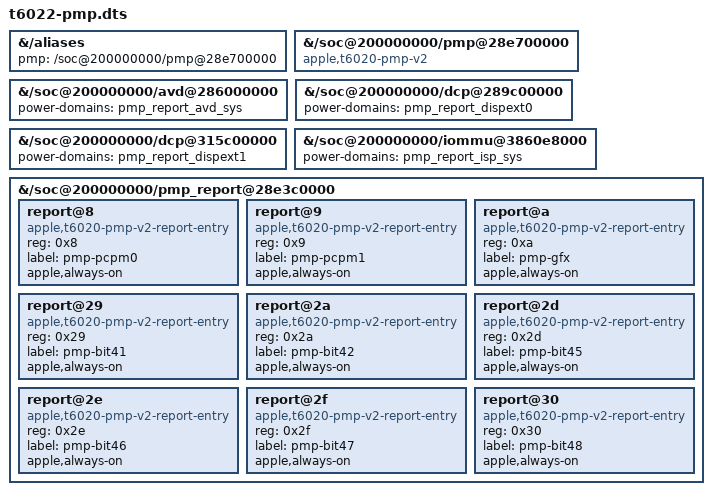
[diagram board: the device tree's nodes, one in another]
// SPDX-License-Identifier: GPL-2.0+ OR MIT
/*
 * The power management processor (PMP) on the M2 Ultra Mac Studio: Asahi's APPLE_USE_PMP for t6022-j475d as an
 * overlay, for die 0, with what that define gets wrong on this machine left out.
 *
 * Asahi's PMP support (drivers/soc/apple/pmp.rs, on for M1 Pro/Max/Ultra since 7.0) is off unless the device tree
 * is built with APPLE_USE_PMP. The define adds the "pmp" alias, which makes m1n1 (1.6.0 and later) copy the ADT's
 * iop-pmp-nub properties into the pmp node as apple,tunable-* and set it okay, and it moves the devices that vote
 * through the PMP report onto its entries. This overlay does the same for die 0; checked 3 Nov 2026 against
 * src/linux (asahi-7.1.13-3 plus the lab series) built with the define: the trees differ only in die 1.
 *
 * Die 1 is not here because Asahi's t6022 wiring for it is wrong (AsahiLinux/linux asahi 414e55d alike):
 *  - its AVD points at pmp_report_avd_sys_die1, which no file defines, so the tree does not compile;
 *  - its two DCPs move to report@1f and report@20, which are die 0's DISPEXT2 and DISPEXT3 (ADT soc-device IDs
 *    32 and 33), and those nodes stay disabled, so the HDMI port's DCP would never get its power domain.
 * The ADT (macOS re-ioreg-IODeviceTree, 28 Oct) gives die 1's devices die 0's soc-device IDs plus 64 (AVD1 82,
 * DISPEXT4 79 for the HDMI port), so die 1 votes in the report's second request word, which pmp-report does not
 * drive. kernel/pmp.sh can set them with its lab module (pmp_votes, VOTES_DIE1=1), but does not by default: macOS
 * wrote no word 1 in the boot traced on 4 Nov, and that day the HDMI display stayed fine with the PMP running and
 * word 1 empty.
 *
 * The pmp node's compatible is cut to "apple,t6020-pmp-v2": the stock pmp.ko matches "apple,t6000-pmp-v2" only and
 * would start the PMP with the M1 family's boot arguments. The lab's pmp series (src-patches/linux/pmp) matches
 * t6020 with the M2 family's, so a kernel built with it starts the PMP at boot; without the series nothing binds
 * and kernel/pmp.sh can start it by hand (votes, start --now).
 *
 * The request word as macOS has it when it starts the PMP (0x0001e6006000c700, traced 4 Nov): the stock entries
 * set DISPEXT0/1 (bits 14, 15) and AFNC4/5_IOA (29, 30) at boot; the entries added below, always on as those are,
 * set the P-CPU clusters (8, 9), the GPU (10) and bits 41, 42 and 45-48, which macOS sets one each after its device
 * requests and no soc-device or pmgr entry names. pmp-report sets an always-on entry's bit when it probes, which is
 * before the pmp module loads. Bits past 31 need the series' first patch (a 64-bit bit in pmp-report).
 *
 * m1n1 adds at most 96 KB to the tree, and with this alias needs about 27 KB more than the ~93 KB it adds today:
 * tbt-kernel.sh pads the board tree when this overlay is applied.
 */
/dts-v1/;
/plugin/;

&{/aliases} {
	pmp = "/soc@200000000/pmp@28e700000";
};

&{/soc@200000000/pmp@28e700000} {
	compatible = "apple,t6020-pmp-v2";
};

&{/soc@200000000/avd@286000000} {
	power-domains = <&pmp_report_avd_sys>;
};

&{/soc@200000000/dcp@289c00000} {
	power-domains = <&pmp_report_dispext0>;
};

&{/soc@200000000/dcp@315c00000} {
	power-domains = <&pmp_report_dispext1>;
};

&{/soc@200000000/iommu@3860e8000} {
	power-domains = <&pmp_report_isp_sys>;
};

&{/soc@200000000/pmp_report@28e3c0000} {
	report@8 {
		compatible = "apple,t6020-pmp-v2-report-entry",
			"apple,t6000-pmp-v2-report-entry";
		reg = <0x8>;
		label = "pmp-pcpm0";
		#power-domain-cells = <0>;
		apple,always-on;
	};

	report@9 {
		compatible = "apple,t6020-pmp-v2-report-entry",
			"apple,t6000-pmp-v2-report-entry";
		reg = <0x9>;
		label = "pmp-pcpm1";
		#power-domain-cells = <0>;
		apple,always-on;
	};

	report@a {
		compatible = "apple,t6020-pmp-v2-report-entry",
			"apple,t6000-pmp-v2-report-entry";
		reg = <0xa>;
		label = "pmp-gfx";
		#power-domain-cells = <0>;
		apple,always-on;
	};

	report@29 {
		compatible = "apple,t6020-pmp-v2-report-entry",
			"apple,t6000-pmp-v2-report-entry";
		reg = <0x29>;
		label = "pmp-bit41";
		#power-domain-cells = <0>;
		apple,always-on;
	};

	report@2a {
		compatible = "apple,t6020-pmp-v2-report-entry",
			"apple,t6000-pmp-v2-report-entry";
		reg = <0x2a>;
		label = "pmp-bit42";
		#power-domain-cells = <0>;
		apple,always-on;
	};

	report@2d {
		compatible = "apple,t6020-pmp-v2-report-entry",
			"apple,t6000-pmp-v2-report-entry";
		reg = <0x2d>;
		label = "pmp-bit45";
		#power-domain-cells = <0>;
		apple,always-on;
	};

	report@2e {
		compatible = "apple,t6020-pmp-v2-report-entry",
			"apple,t6000-pmp-v2-report-entry";
		reg = <0x2e>;
		label = "pmp-bit46";
		#power-domain-cells = <0>;
		apple,always-on;
	};

	report@2f {
		compatible = "apple,t6020-pmp-v2-report-entry",
			"apple,t6000-pmp-v2-report-entry";
		reg = <0x2f>;
		label = "pmp-bit47";
		#power-domain-cells = <0>;
		apple,always-on;
	};

	report@30 {
		compatible = "apple,t6020-pmp-v2-report-entry",
			"apple,t6000-pmp-v2-report-entry";
		reg = <0x30>;
		label = "pmp-bit48";
		#power-domain-cells = <0>;
		apple,always-on;
	};
};
